# APM32F41x register map
File version: 1.0
CPU: CM4 r1p0, little endian, no MPU, no FPU, 3 interrupt priority bits
Registers are 32-bit, read-write, reset 0x0 unless marked. A register's access mark holds for its fields unless they carry their own. Offsets are from the block's base; [hi:lo] are bit positions; {n}, {i} and the like mark numbered series.

## RCM — Reset and clock control
Base 0x40023800
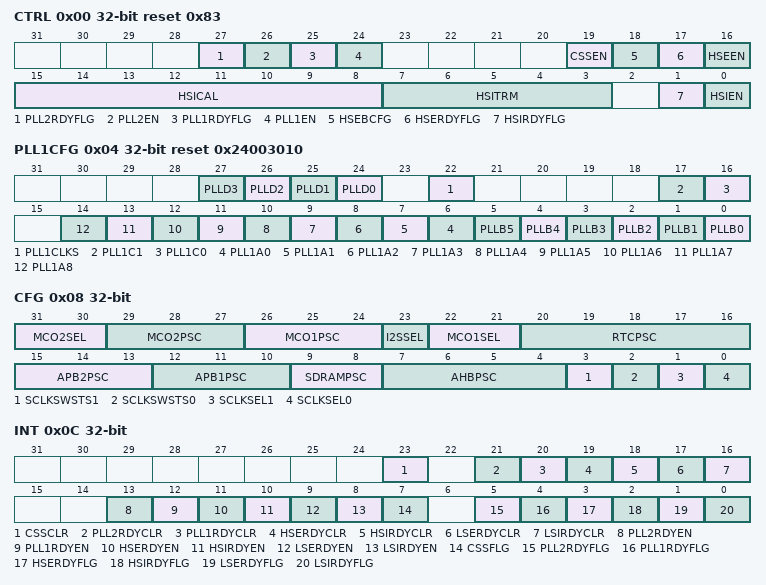
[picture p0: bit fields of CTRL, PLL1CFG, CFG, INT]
0x00 CTRL access per field reset 0x83 — clock control register
  [27] PLL2RDYFLG ro — PLLI2S clock ready flag
  [26] PLL2EN rw — PLLI2S enable
  [25] PLL1RDYFLG ro — Main PLL (PLL) clock ready flag
  [24] PLL1EN rw — Main PLL (PLL) enable
  [19] CSSEN rw — Clock security system enable
  [18] HSEBCFG rw — HSE clock bypass
  [17] HSERDYFLG ro — HSE clock ready flag
  [16] HSEEN rw — HSE clock enable
  [15:8] HSICAL ro — Internal high-speed clock calibration
  [7:3] HSITRM rw — Internal high-speed clock trimming
  [1] HSIRDYFLG ro — Internal high-speed clock ready flag
  [0] HSIEN rw — Internal high-speed clock enable
0x04 PLL1CFG reset 0x24003010 — PLL configuration register
  [n+24] PLLD{n} (n=0..3) — Main PLL (PLL) division factor for USB OTG FS, SDIO and random number generator clocks
  [22] PLL1CLKS — Main PLL(PLL) and audio PLL (PLLI2S) entry clock source
  [17] PLL1C1 — Main PLL (PLL) division factor for main system clock
  [16] PLL1C0 — Main PLL (PLL) division factor for main system clock
  [n+6] PLL1A{n} (n=0..8) — Main PLL (PLL) multiplication factor for VCO
  [n] PLLB{n} (n=0..5) — Division factor for the main PLL (PLL) and audio PLL (PLLI2S) input clock
0x08 CFG access per field — clock configuration register
  [31:30] MCO2SEL rw — Microcontroller clock output 2
  [29:27] MCO2PSC rw — MCO2 prescaler
  [26:24] MCO1PSC rw — MCO1 prescaler
  [23] I2SSEL rw — I2S clock selection
  [22:21] MCO1SEL rw — Microcontroller clock output 1
  [20:16] RTCPSC rw — HSE division factor for RTC clock
  [15:13] APB2PSC rw — APB high-speed prescaler (APB2)
  [12:10] APB1PSC rw — APB Low speed prescaler (APB1)
  [9:8] SDRAMPSC rw — SDRAM Clock Prescaler Factor Configure
  [7:4] AHBPSC rw — AHB prescaler
  [3] SCLKSWSTS1 ro — System clock switch status
  [2] SCLKSWSTS0 ro — System clock switch status
  [1] SCLKSEL1 rw — System clock switch
  [0] SCLKSEL0 rw — System clock switch
0x0C INT access per field — clock interrupt register
  [23] CSSCLR wo — Clock security system interrupt clear
  [21] PLL2RDYCLR wo — PLLI2S ready interrupt clear
  [20] PLL1RDYCLR wo — Main PLL(PLL) ready interrupt clear
  [19] HSERDYCLR wo — HSE ready interrupt clear
  [18] HSIRDYCLR wo — HSI ready interrupt clear
  [17] LSERDYCLR wo — LSE ready interrupt clear
  [16] LSIRDYCLR wo — LSI ready interrupt clear
  [13] PLL2RDYEN rw — PLLI2S ready interrupt enable
  [12] PLL1RDYEN rw — Main PLL (PLL) ready interrupt enable
  [11] HSERDYEN rw — HSE ready interrupt enable
  [10] HSIRDYEN rw — HSI ready interrupt enable
  [9] LSERDYEN rw — LSE ready interrupt enable
  [8] LSIRDYEN rw — LSI ready interrupt enable
  [7] CSSFLG ro — Clock security system interrupt flag
  [5] PLL2RDYFLG ro — PLLI2S ready interrupt flag
  [4] PLL1RDYFLG ro — Main PLL (PLL) ready interrupt flag
  [3] HSERDYFLG ro — HSE ready interrupt flag
  [2] HSIRDYFLG ro — HSI ready interrupt flag
  [1] LSERDYFLG ro — LSE ready interrupt flag
  [0] LSIRDYFLG ro — LSI ready interrupt flag
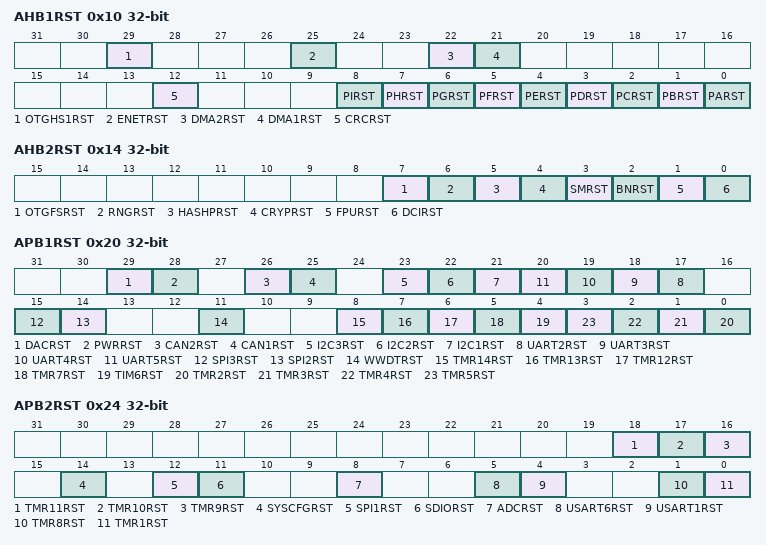
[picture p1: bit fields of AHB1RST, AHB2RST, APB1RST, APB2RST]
0x10 AHB1RST — AHB1 peripheral reset register
  [29] OTGHS1RST — USB OTG HS module reset
  [25] ENETRST — Ethernet MAC reset
  [22] DMA2RST — DMA2 reset
  [21] DMA1RST — DMA2 reset
  [12] CRCRST — CRC reset
  [8] PIRST — IO port I reset
  [7] PHRST — IO port H reset
  [6] PGRST — IO port G reset
  [5] PFRST — IO port F reset
  [4] PERST — IO port E reset
  [3] PDRST — IO port D reset
  [2] PCRST — IO port C reset
  [1] PBRST — IO port B reset
  [0] PARST — IO port A reset
0x14 AHB2RST — AHB2 peripheral reset register
  [7] OTGFSRST — USB OTG FS module reset
  [6] RNGRST — Random number generator module reset
  [5] HASHPRST — HASHP Reset
  [4] CRYPRST — CRYP Reset
  [3] SMRST — SM reset
  [2] BNRST — BN reset
  [1] FPURST — FPU reset
  [0] DCIRST — Camera interface reset
0x18 AHB3RST — AHB3 peripheral reset register
  [0] EMMCRST — Flexible static memory controller module reset
0x20 APB1RST — APB1 peripheral reset register
  [29] DACRST — DAC reset
  [28] PWRRST — Power interface reset
  [26] CAN2RST — CAN2 reset
  [25] CAN1RST — CAN1 reset
  [23] I2C3RST — I2C3 reset
  [22] I2C2RST — I2C 2 reset
  [21] I2C1RST — I2C 1 reset
  [n+15] UART{n}RST (n=2..5) — USART {n} reset
  [15] SPI3RST — SPI 3 reset
  [14] SPI2RST — SPI 2 reset
  [11] WWDTRST — Window watchdog reset
  [8] TMR14RST — TMR14 reset
  [7] TMR13RST — TMR13 reset
  [6] TMR12RST — TMR12 reset
  [5] TMR7RST — TMR7 reset
  [4] TIM6RST — TIM6 reset
  [n-2] TMR{n}RST (n=2..5) — TMR{n} reset
0x24 APB2RST — APB2 peripheral reset register
  [18] TMR11RST — TMR11 reset
  [17] TMR10RST — TMR10 reset
  [16] TMR9RST — TMR9 reset
  [14] SYSCFGRST — System configuration controller reset
  [12] SPI1RST — SPI 1 reset
  [11] SDIORST — SDIO reset
  [8] ADCRST — ADC interface reset (common to all ADCs)
  [5] USART6RST — USART6 reset
  [4] USART1RST — USART1 reset
  [1] TMR8RST — TMR8 reset
  [0] TMR1RST — TMR1 reset
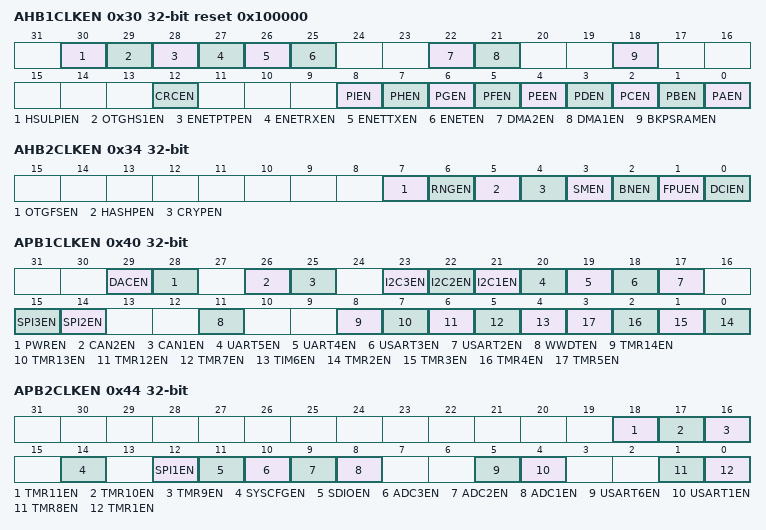
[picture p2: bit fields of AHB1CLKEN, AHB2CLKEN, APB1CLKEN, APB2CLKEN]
0x30 AHB1CLKEN reset 0x100000 — AHB1 peripheral clock register
  [30] HSULPIEN — USB OTG HSULPI clock enable
  [29] OTGHS1EN — USB OTG HS clock enable
  [28] ENETPTPEN — Ethernet PTP clock enable
  [27] ENETRXEN — Ethernet Reception clock enable
  [26] ENETTXEN — Ethernet Transmission clock enable
  [25] ENETEN — Ethernet MAC clock enable
  [22] DMA2EN — DMA2 clock enable
  [21] DMA1EN — DMA1 clock enable
  [18] BKPSRAMEN — Backup SRAM interface clock enable
  [12] CRCEN — CRC clock enable
  [8] PIEN — IO port I clock enable
  [7] PHEN — IO port H clock enable
  [6] PGEN — IO port G clock enable
  [5] PFEN — IO port F clock enable
  [4] PEEN — IO port E clock enable
  [3] PDEN — IO port D clock enable
  [2] PCEN — IO port C clock enable
  [1] PBEN — IO port B clock enable
  [0] PAEN — IO port A clock enable
0x34 AHB2CLKEN — AHB2 peripheral clock enable register
  [7] OTGFSEN — USB OTG FS clock enable
  [6] RNGEN — Random number generator clock enable
  [5] HASHPEN — HASHP enable
  [4] CRYPEN — CRYP enable
  [3] SMEN — SM enable
  [2] BNEN — BN enable
  [1] FPUEN — FPU enable
  [0] DCIEN — Camera interface enable
0x38 AHB3CLKEN — AHB3 peripheral clock enable register
  [0] EMMCEN — Flexible static memory controller module clock enable
0x40 APB1CLKEN — APB1 peripheral clock enable register
  [29] DACEN — DAC interface clock enable
  [28] PWREN — Power interface clock enable
  [26] CAN2EN — CAN 2 clock enable
  [25] CAN1EN — CAN 1 clock enable
  [23] I2C3EN — I2C3 clock enable
  [22] I2C2EN — I2C2 clock enable
  [21] I2C1EN — I2C1 clock enable
  [20] UART5EN — UART5 clock enable
  [19] UART4EN — UART4 clock enable
  [18] USART3EN — USART3 clock enable
  [17] USART2EN — USART 2 clock enable
  [15] SPI3EN — SPI3 clock enable
  [14] SPI2EN — SPI2 clock enable
  [11] WWDTEN — Window watchdog clock enable
  [8] TMR14EN — TMR14 clock enable
  [7] TMR13EN — TMR13 clock enable
  [6] TMR12EN — TMR12 clock enable
  [5] TMR7EN — TMR7 clock enable
  [4] TIM6EN — TIM6 clock enable
  [n-2] TMR{n}EN (n=2..5) — TMR{n} clock enable
0x44 APB2CLKEN — APB2 peripheral clock enable register
  [18] TMR11EN — TMR11 clock enable
  [17] TMR10EN — TMR10 clock enable
  [16] TMR9EN — TMR9 clock enable
  [14] SYSCFGEN — System configuration controller clock enable
  [12] SPI1EN — SPI1 clock enable
  [11] SDIOEN — SDIO clock enable
  [10] ADC3EN — ADC3 clock enable
  [9] ADC2EN — ADC2 clock enable
  [8] ADC1EN — ADC1 clock enable
  [5] USART6EN — USART6 clock enable
  [4] USART1EN — USART1 clock enable
  [1] TMR8EN — TMR8 clock enable
  [0] TMR1EN — TMR1 clock enable
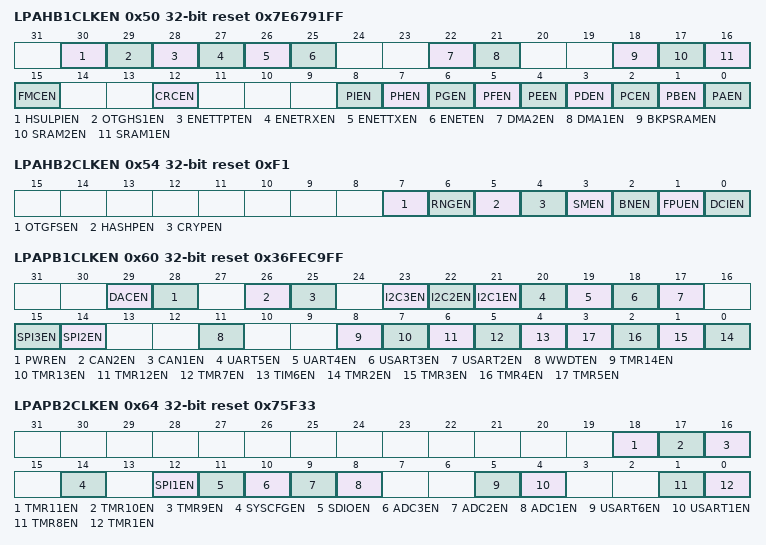
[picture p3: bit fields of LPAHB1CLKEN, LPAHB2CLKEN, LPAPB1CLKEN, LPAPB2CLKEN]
0x50 LPAHB1CLKEN reset 0x7E6791FF — AHB1 peripheral clock enable in low power mode register
  [30] HSULPIEN — USB OTG HS ULPI clock enable during Sleep mode
  [29] OTGHS1EN — USB OTG HS clock enable during Sleep mode
  [28] ENETTPTEN — Ethernet PTP clock enable during Sleep mode
  [27] ENETRXEN — Ethernet reception clock enable during Sleep mode
  [26] ENETTXEN — Ethernet transmission clock enable during Sleep mode
  [25] ENETEN — Ethernet MAC clock enable during Sleep mode
  [22] DMA2EN — DMA2 clock enable during Sleep mode
  [21] DMA1EN — DMA1 clock enable during Sleep mode
  [18] BKPSRAMEN — Backup SRAM interface clock enable during Sleep mode
  [17] SRAM2EN — SRAM 2 interface clock enable during Sleep mode
  [16] SRAM1EN — SRAM 1interface clock enable during Sleep mode
  [15] FMCEN — Flash interface clock enable during Sleep mode
  [12] CRCEN — CRC clock enable during Sleep mode
  [8] PIEN — IO port I clock enable during Sleep mode
  [7] PHEN — IO port H clock enable during Sleep mode
  [6] PGEN — IO port G clock enable during Sleep mode
  [5] PFEN — IO port F clock enable during Sleep mode
  [4] PEEN — IO port E clock enable during Sleep mode
  [3] PDEN — IO port D clock enable during Sleep mode
  [2] PCEN — IO port C clock enable during Sleep mode
  [1] PBEN — IO port B clock enable during Sleep mode
  [0] PAEN — IO port A clock enable during sleep mode
0x54 LPAHB2CLKEN reset 0xF1 — AHB2 peripheral clock enable in low power mode register
  [7] OTGFSEN — USB OTG FS clock enable during Sleep mode
  [6] RNGEN — Random number generator clock enable during Sleep mode
  [5] HASHPEN — HASHP enable during Sleep mode
  [4] CRYPEN — CRYP enable during Sleep mode
  [3] SMEN — SM enable during Sleep mode
  [2] BNEN — BN enable during Sleep mode
  [1] FPUEN — FPU enable during Sleep mode
  [0] DCIEN — Camera interface enable during Sleep mode
0x58 LPAHB3CLKEN reset 0x1 — AHB3 peripheral clock enable in low power mode register
  [0] EMMCEN — Flexible static memory controller module clock enable during Sleep mode
0x60 LPAPB1CLKEN reset 0x36FEC9FF — APB1 peripheral clock enable in low power mode register
  [29] DACEN — DAC interface clock enable during Sleep mode
  [28] PWREN — Power interface clock enable during Sleep mode
  [26] CAN2EN — CAN 2 clock enable during Sleep mode
  [25] CAN1EN — CAN 1 clock enable during Sleep mode
  [23] I2C3EN — I2C3 clock enable during Sleep mode
  [22] I2C2EN — I2C2 clock enable during Sleep mode
  [21] I2C1EN — I2C1 clock enable during Sleep mode
  [20] UART5EN — UART5 clock enable during Sleep mode
  [19] UART4EN — UART4 clock enable during Sleep mode
  [18] USART3EN — USART3 clock enable during Sleep mode
  [17] USART2EN — USART2 clock enable during Sleep mode
  [15] SPI3EN — SPI3 clock enable during Sleep mode
  [14] SPI2EN — SPI2 clock enable during Sleep mode
  [11] WWDTEN — Window watchdog clock enable during Sleep mode
  [8] TMR14EN — TMR14 clock enable during Sleep mode
  [7] TMR13EN — TMR13 clock enable during Sleep mode
  [6] TMR12EN — TMR12 clock enable during Sleep mode
  [5] TMR7EN — TMR7 clock enable during Sleep mode
  [4] TIM6EN — TIM6 clock enable during Sleep mode
  [n-2] TMR{n}EN (n=2..5) — TMR{n} clock enable during Sleep mode
0x64 LPAPB2CLKEN reset 0x75F33 — APB2 peripheral clock enabled in low power mode register
  [18] TMR11EN — TMR11 clock enable during Sleep mode
  [17] TMR10EN — TMR10 clock enable during Sleep mode
  [16] TMR9EN — TMR9 clock enable during sleep mode
  [14] SYSCFGEN — System configuration controller clock enable during Sleep mode
  [12] SPI1EN — SPI 1 clock enable during Sleep mode
  [11] SDIOEN — SDIO clock enable during Sleep mode
  [10] ADC3EN — ADC 3 clock enable during Sleep mode
  [9] ADC2EN — ADC2 clock enable during Sleep mode
  [8] ADC1EN — ADC1 clock enable during Sleep mode
  [5] USART6EN — USART6 clock enable during Sleep mode
  [4] USART1EN — USART1 clock enable during Sleep mode
  [1] TMR8EN — TMR8 clock enable during Sleep mode
  [0] TMR1EN — TMR1 clock enable during Sleep mode
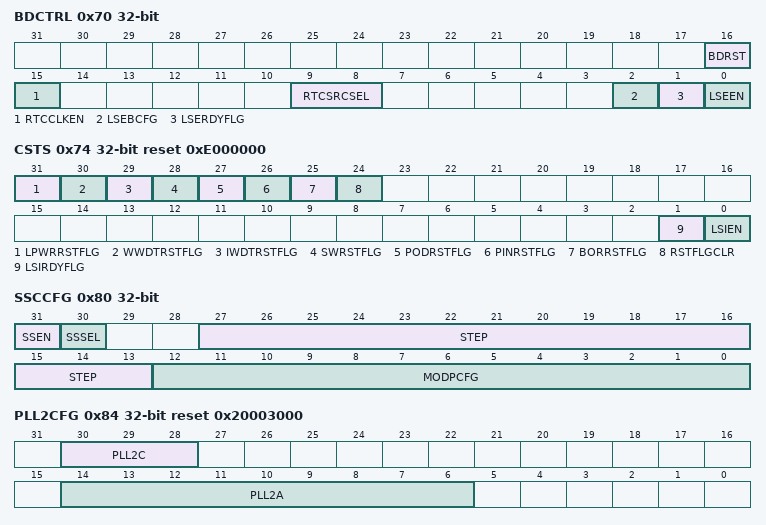
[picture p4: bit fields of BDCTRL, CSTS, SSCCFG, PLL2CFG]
0x70 BDCTRL access per field — Backup domain control register
  [16] BDRST rw — Backup domain software reset
  [15] RTCCLKEN rw — RTC clock enable
  [9:8] RTCSRCSEL rw — RTC clock source selection
  [2] LSEBCFG rw — External low-speed oscillator bypass
  [1] LSERDYFLG ro — External low-speed oscillator ready
  [0] LSEEN rw — External low-speed oscillator enable
0x74 CSTS access per field reset 0xE000000 — clock control & status register
  [31] LPWRRSTFLG rw — Low-power reset flag
  [30] WWDTRSTFLG rw — Window watchdog reset flag
  [29] IWDTRSTFLG rw — Independent watchdog reset flag
  [28] SWRSTFLG rw — Software reset flag
  [27] PODRSTFLG rw — POR/PDR reset flag
  [26] PINRSTFLG rw — PIN reset flag
  [25] BORRSTFLG rw — BOR reset flag
  [24] RSTFLGCLR rw — Remove reset flag
  [1] LSIRDYFLG ro — Internal low-speed oscillator ready
  [0] LSIEN rw — Internal low-speed oscillator enable
0x80 SSCCFG — spread spectrum clock generation register
  [31] SSEN — Spread spectrum modulation enable
  [30] SSSEL — Spread Select
  [27:13] STEP — Incrementation step
  [12:0] MODPCFG — Modulation period
0x84 PLL2CFG reset 0x20003000 — PLLI2S configuration register
  [30:28] PLL2C — PLLI2S division factor for I2S clocks
  [14:6] PLL2A — PLLI2S multiplication factor for VCO
